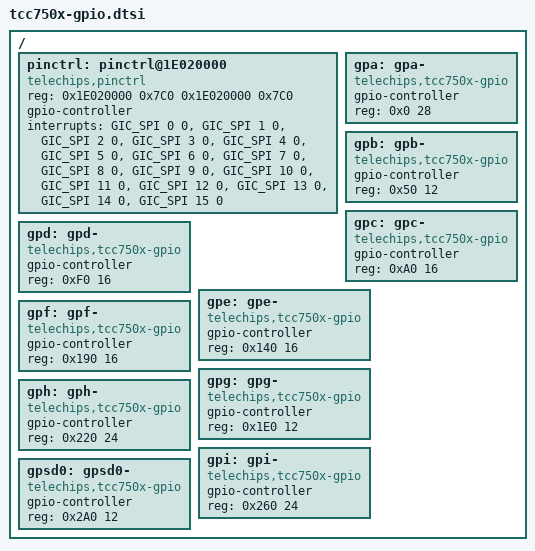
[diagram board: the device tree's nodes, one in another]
// SPDX-License-Identifier: (GPL-2.0-or-later OR MIT)
/*
 * Copyright (C) 2023 Telechips Inc.
 */

#include <dt-bindings/interrupt-controller/arm-gic.h>
#include <dt-bindings/gpio/gpio.h>

/ {
	pinctrl: pinctrl@1E020000 {
		compatible = "telechips,pinctrl";
		reg = <0x1E020000 0x7C0 0x1E020000 0x7C0>; /* gpio */
		gpio-controller;
		#address-cells = <1>;
		#size-cells = <0>;
		#gpio-cells = <3>;
		interrupts = <GIC_SPI 0 0>,
			     <GIC_SPI 1 0>,
			     <GIC_SPI 2 0>,
			     <GIC_SPI 3 0>,
			     <GIC_SPI 4 0>,
			     <GIC_SPI 5 0>,
			     <GIC_SPI 6 0>,
			     <GIC_SPI 7 0>,
			     <GIC_SPI 8 0>,
			     <GIC_SPI 9 0>,
			     <GIC_SPI 10 0>,
			     <GIC_SPI 11 0>,
			     <GIC_SPI 12 0>,
			     <GIC_SPI 13 0>,
			     <GIC_SPI 14 0>,
			     <GIC_SPI 15 0>;
	};

	gpa: gpa- {
		compatible = "telechips,tcc750x-gpio";
		gpio-controller;
		#gpio-cells = <2>;
		reg = <0x0 28>;
	};

	gpb: gpb- {
		compatible = "telechips,tcc750x-gpio";
		gpio-controller;
		#gpio-cells = <2>;
		reg = <0x50 12>;
	};

	gpc: gpc- {
		compatible = "telechips,tcc750x-gpio";
		gpio-controller;
		#gpio-cells = <2>;
		reg = <0xA0 16>;
	};

	gpd: gpd- {
		compatible = "telechips,tcc750x-gpio";
		gpio-controller;
		#gpio-cells = <2>;
		reg = <0xF0 16>;
	};

	gpe: gpe- {
		compatible = "telechips,tcc750x-gpio";
		gpio-controller;
		#gpio-cells = <2>;
		reg = <0x140 16>;
	};

	gpf: gpf- {
		compatible = "telechips,tcc750x-gpio";
		gpio-controller;
		#gpio-cells = <2>;
		reg = <0x190 16>;
	};

	gpg: gpg- {
		compatible = "telechips,tcc750x-gpio";
		gpio-controller;
		#gpio-cells = <2>;
		reg = <0x1E0 12>;
	};

	gph: gph- {
		compatible = "telechips,tcc750x-gpio";
		gpio-controller;
		#gpio-cells = <2>;
		reg = <0x220 24>;
	};

	gpi: gpi- {
		compatible = "telechips,tcc750x-gpio";
		gpio-controller;
		#gpio-cells = <2>;
		reg = <0x260 24>;
	};

	gpsd0: gpsd0- {
		compatible = "telechips,tcc750x-gpio";
		gpio-controller;
		#gpio-cells = <2>;
		reg = <0x2A0 12>;
	};
};
